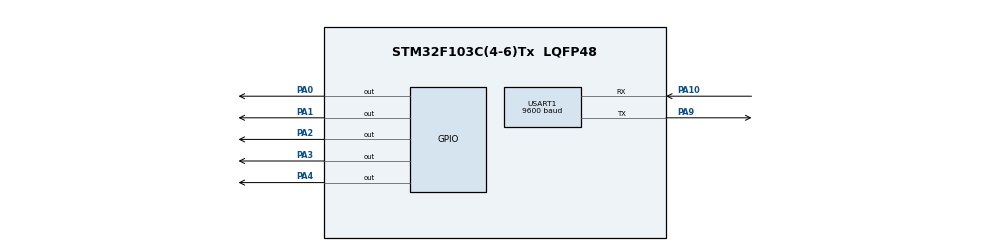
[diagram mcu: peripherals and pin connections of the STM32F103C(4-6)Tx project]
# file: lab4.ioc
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Mcu.Family=STM32F1
Mcu.Name=STM32F103C(4-6)Tx
Mcu.Package=LQFP48
NVIC.PriorityGroup=NVIC_PRIORITYGROUP_4
NVIC.TIM2_IRQn=true\:0\:0\:false\:false\:true\:true\:true
NVIC.TIM3_IRQn=true\:0\:0\:false\:false\:true\:true\:true
PA0-WKUP.Signal=GPIO_Output
PA1.Signal=GPIO_Output
PA10.Mode=Asynchronous
PA10.Signal=USART1_RX
PA2.Signal=GPIO_Output
PA3.Signal=GPIO_Output
PA4.Signal=GPIO_Output
PA9.Mode=Asynchronous
PA9.Signal=USART1_TX
PD0-OSC_IN.Mode=HSE-External-Oscillator
PD0-OSC_IN.Signal=RCC_OSC_IN
PD1-OSC_OUT.Mode=HSE-External-Oscillator
PD1-OSC_OUT.Signal=RCC_OSC_OUT
ProjectManager.HeapSize=0x200
ProjectManager.StackSize=0x400
ProjectManager.TargetToolchain=STM32CubeIDE
RCC.APB1Freq_Value=8000000
RCC.APB2Freq_Value=8000000
RCC.SYSCLKSource=RCC_SYSCLKSOURCE_HSE
TIM2.Period=10 - 1
TIM2.Prescaler=8000 - 1
TIM3.Period=500 - 1
TIM3.Prescaler=8000
USART1.BaudRate=9600
USART1.VirtualMode=VM_ASYNC
VP_SYS_VS_ND.Mode=No_Debug
VP_TIM2_VS_ClockSourceINT.Mode=Internal
VP_TIM3_VS_ClockSourceINT.Mode=Internal
board=custom

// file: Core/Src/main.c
/* USER CODE BEGIN Header */
/**
  ******************************************************************************
  * @file           : main.c
  * @brief          : Main program body
  ******************************************************************************
  * @attention
  *
  * <h2><center>&copy; Copyright (c) 2021 STMicroelectronics.
  * All rights reserved.</center></h2>
  *
  * This software component is licensed by ST under BSD 3-Clause license,
  * the "License"; You may not use this file except in compliance with the
  * License. You may obtain a copy of the License at:
  *                        opensource.org/licenses/BSD-3-Clause
  *
  ******************************************************************************
  */
/* USER CODE END Header */
#include "main.h"

/* USER CODE BEGIN Includes */
#include "scheduler.h"
#include "tasks.h"
/* USER CODE END Includes */

TIM_HandleTypeDef htim2;
TIM_HandleTypeDef htim3;

//UART_HandleTypeDef huart1;

void SystemClock_Config(void);
static void MX_GPIO_Init(void);
static void MX_USART1_UART_Init(void);
static void MX_TIM2_Init(void);
static void MX_TIM3_Init(void);

int main(void)
{

  /* MCU Configuration--------------------------------------------------------*/

  /* Reset of all peripherals, Initializes the Flash interface and the Systick. */
  HAL_Init();

  /* Configure the system clock */
  SystemClock_Config();

  /* Initialize all configured peripherals */
  MX_GPIO_Init();
  MX_USART1_UART_Init();
  MX_TIM2_Init();
  MX_TIM3_Init();
  /* USER CODE BEGIN 2 */
  HAL_TIM_Base_Start_IT(&htim2);
  HAL_TIM_Base_Start_IT(&htim3);

  SCH_Init();
  //1 tick = 10ms
  SCH_Add_Task(&task0, 10, 50);
  SCH_Add_Task(&task1, 11, 100);
  SCH_Add_Task(&task2, 12, 150);
  SCH_Add_Task(&task3, 13, 200);
  SCH_Add_Task(&task4, 14, 250);
  /* USER CODE END 2 */

  /* Infinite loop */
  while (1)
  {
	 SCH_Dispatch_Tasks();
  }
}

void SystemClock_Config(void)
{
  RCC_OscInitTypeDef RCC_OscInitStruct = {0};
  RCC_ClkInitTypeDef RCC_ClkInitStruct = {0};

  /** Initializes the RCC Oscillators according to the specified parameters
  * in the RCC_OscInitTypeDef structure.
  */
  RCC_OscInitStruct.OscillatorType = RCC_OSCILLATORTYPE_HSE;
  RCC_OscInitStruct.HSEState = RCC_HSE_ON;
  RCC_OscInitStruct.PLL.PLLState = RCC_PLL_NONE;
  if (HAL_RCC_OscConfig(&RCC_OscInitStruct) != HAL_OK)
  {
    Error_Handler();
  }
  /** Initializes the CPU, AHB and APB buses clocks
  */
  RCC_ClkInitStruct.ClockType = RCC_CLOCKTYPE_HCLK|RCC_CLOCKTYPE_SYSCLK
                              |RCC_CLOCKTYPE_PCLK1|RCC_CLOCKTYPE_PCLK2;
  RCC_ClkInitStruct.SYSCLKSource = RCC_SYSCLKSOURCE_HSE;
  RCC_ClkInitStruct.AHBCLKDivider = RCC_SYSCLK_DIV1;
  RCC_ClkInitStruct.APB1CLKDivider = RCC_HCLK_DIV1;
  RCC_ClkInitStruct.APB2CLKDivider = RCC_HCLK_DIV1;

  if (HAL_RCC_ClockConfig(&RCC_ClkInitStruct, FLASH_LATENCY_0) != HAL_OK)
  {
    Error_Handler();
  }
}

static void MX_TIM2_Init(void)
{

  TIM_ClockConfigTypeDef sClockSourceConfig = {0};
  TIM_MasterConfigTypeDef sMasterConfig = {0};

  htim2.Instance = TIM2;
  htim2.Init.Prescaler = 8000 - 1;
  htim2.Init.CounterMode = TIM_COUNTERMODE_UP;
  htim2.Init.Period = 10 - 1;
  htim2.Init.ClockDivision = TIM_CLOCKDIVISION_DIV1;
  htim2.Init.AutoReloadPreload = TIM_AUTORELOAD_PRELOAD_DISABLE;
  if (HAL_TIM_Base_Init(&htim2) != HAL_OK)
  {
    Error_Handler();
  }
  sClockSourceConfig.ClockSource = TIM_CLOCKSOURCE_INTERNAL;
  if (HAL_TIM_ConfigClockSource(&htim2, &sClockSourceConfig) != HAL_OK)
  {
    Error_Handler();
  }
  sMasterConfig.MasterOutputTrigger = TIM_TRGO_RESET;
  sMasterConfig.MasterSlaveMode = TIM_MASTERSLAVEMODE_DISABLE;
  if (HAL_TIMEx_MasterConfigSynchronization(&htim2, &sMasterConfig) != HAL_OK)
  {
    Error_Handler();
  }

}

static void MX_TIM3_Init(void)
{

  TIM_ClockConfigTypeDef sClockSourceConfig = {0};
  TIM_MasterConfigTypeDef sMasterConfig = {0};

  htim3.Instance = TIM3;
  htim3.Init.Prescaler = 8000;
  htim3.Init.CounterMode = TIM_COUNTERMODE_UP;
  htim3.Init.Period = 500 - 1;
  htim3.Init.ClockDivision = TIM_CLOCKDIVISION_DIV1;
  htim3.Init.AutoReloadPreload = TIM_AUTORELOAD_PRELOAD_DISABLE;
  if (HAL_TIM_Base_Init(&htim3) != HAL_OK)
  {
    Error_Handler();
  }
  sClockSourceConfig.ClockSource = TIM_CLOCKSOURCE_INTERNAL;
  if (HAL_TIM_ConfigClockSource(&htim3, &sClockSourceConfig) != HAL_OK)
  {
    Error_Handler();
  }
  sMasterConfig.MasterOutputTrigger = TIM_TRGO_RESET;
  sMasterConfig.MasterSlaveMode = TIM_MASTERSLAVEMODE_DISABLE;
  if (HAL_TIMEx_MasterConfigSynchronization(&htim3, &sMasterConfig) != HAL_OK)
  {
    Error_Handler();
  }

}

static void MX_USART1_UART_Init(void)
{

  huart1.Instance = USART1;
  huart1.Init.BaudRate = 9600;
  huart1.Init.WordLength = UART_WORDLENGTH_8B;
  huart1.Init.StopBits = UART_STOPBITS_1;
  huart1.Init.Parity = UART_PARITY_NONE;
  huart1.Init.Mode = UART_MODE_TX_RX;
  huart1.Init.HwFlowCtl = UART_HWCONTROL_NONE;
  huart1.Init.OverSampling = UART_OVERSAMPLING_16;
  if (HAL_UART_Init(&huart1) != HAL_OK)
  {
    Error_Handler();
  }

}

static void MX_GPIO_Init(void)
{
  GPIO_InitTypeDef GPIO_InitStruct = {0};

  /* GPIO Ports Clock Enable */
  __HAL_RCC_GPIOD_CLK_ENABLE();
  __HAL_RCC_GPIOA_CLK_ENABLE();

  /*Configure GPIO pin Output Level */
  HAL_GPIO_WritePin(GPIOA, GPIO_PIN_0|GPIO_PIN_1|GPIO_PIN_2|GPIO_PIN_3
                          |GPIO_PIN_4, GPIO_PIN_RESET);

  /*Configure GPIO pins : PA0 PA1 PA2 PA3
                           PA4 */
  GPIO_InitStruct.Pin = GPIO_PIN_0|GPIO_PIN_1|GPIO_PIN_2|GPIO_PIN_3
                          |GPIO_PIN_4;
  GPIO_InitStruct.Mode = GPIO_MODE_OUTPUT_PP;
  GPIO_InitStruct.Pull = GPIO_NOPULL;
  GPIO_InitStruct.Speed = GPIO_SPEED_FREQ_LOW;
  HAL_GPIO_Init(GPIOA, &GPIO_InitStruct);

}

/* USER CODE BEGIN 4 */
//uint32_t timer_curr_time[2] = {0, 0};

void HAL_TIM_PeriodElapsedCallback (TIM_HandleTypeDef *htim) {
	//uint8_t *uart_buf;
	//uint8_t uart_buf_len;
	if (htim->Instance == TIM2) {
		//uint32_t period = __HAL_TIM_GET_COUNTER(&htim2) - timer_curr_time[0];
		//uart_buf_len = sprintf(uart_buf, "#%lu timer2 callback called\r\n", period);
		//timer_curr_time[0] = __HAL_TIM_GET_COUNTER(&htim2);
		//HAL_UART_Transmit(&huart1, uart_buf, uart_buf_len, 100);
		SCH_Update();
	}

	else if (htim->Instance == TIM3) {
		//uart_buf_len = sprintf(uart_buf, "#%lu timer3 callback called\r\n", __HAL_TIM_GET_COUNTER(&htim3) - timer_curr_time[1]);
		//timer_curr_time[1] = __HAL_TIM_GET_COUNTER(&htim3);
		//HAL_UART_Transmit(&huart1, uart_buf, uart_buf_len, 100);
	}
}
/* USER CODE END 4 */

void Error_Handler(void)
{
  __disable_irq();
  while (1)
  {
  }
}

/************************ (C) COPYRIGHT STMicroelectronics *****END OF FILE****/
